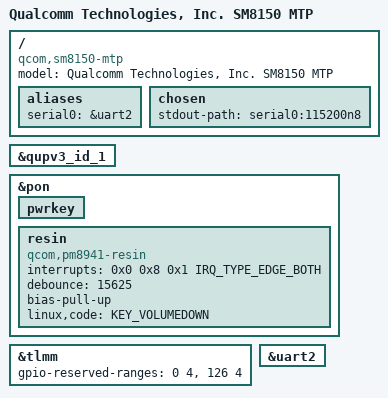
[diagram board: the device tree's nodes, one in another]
// SPDX-License-Identifier: BSD-3-Clause
/*
 * Copyright (c) 2017-2019, The Linux Foundation. All rights reserved.
 * Copyright (c) 2019, Linaro Limited
 */

/dts-v1/;

#include "sm8150.dtsi"
#include "pm8150.dtsi"
#include "pm8150b.dtsi"
#include "pm8150l.dtsi"

/ {
	model = "Qualcomm Technologies, Inc. SM8150 MTP";
	compatible = "qcom,sm8150-mtp";

	aliases {
		serial0 = &uart2;
	};

	chosen {
		stdout-path = "serial0:115200n8";
	};
};

&qupv3_id_1 {
	status = "okay";
};

&pon {
	pwrkey {
		status = "okay";
	};

	resin {
		compatible = "qcom,pm8941-resin";
		interrupts = <0x0 0x8 0x1 IRQ_TYPE_EDGE_BOTH>;
		debounce = <15625>;
		bias-pull-up;
		linux,code = <KEY_VOLUMEDOWN>;
	};
};

&tlmm {
	gpio-reserved-ranges = <0 4>, <126 4>;
};

&uart2 {
	status = "okay";
};
